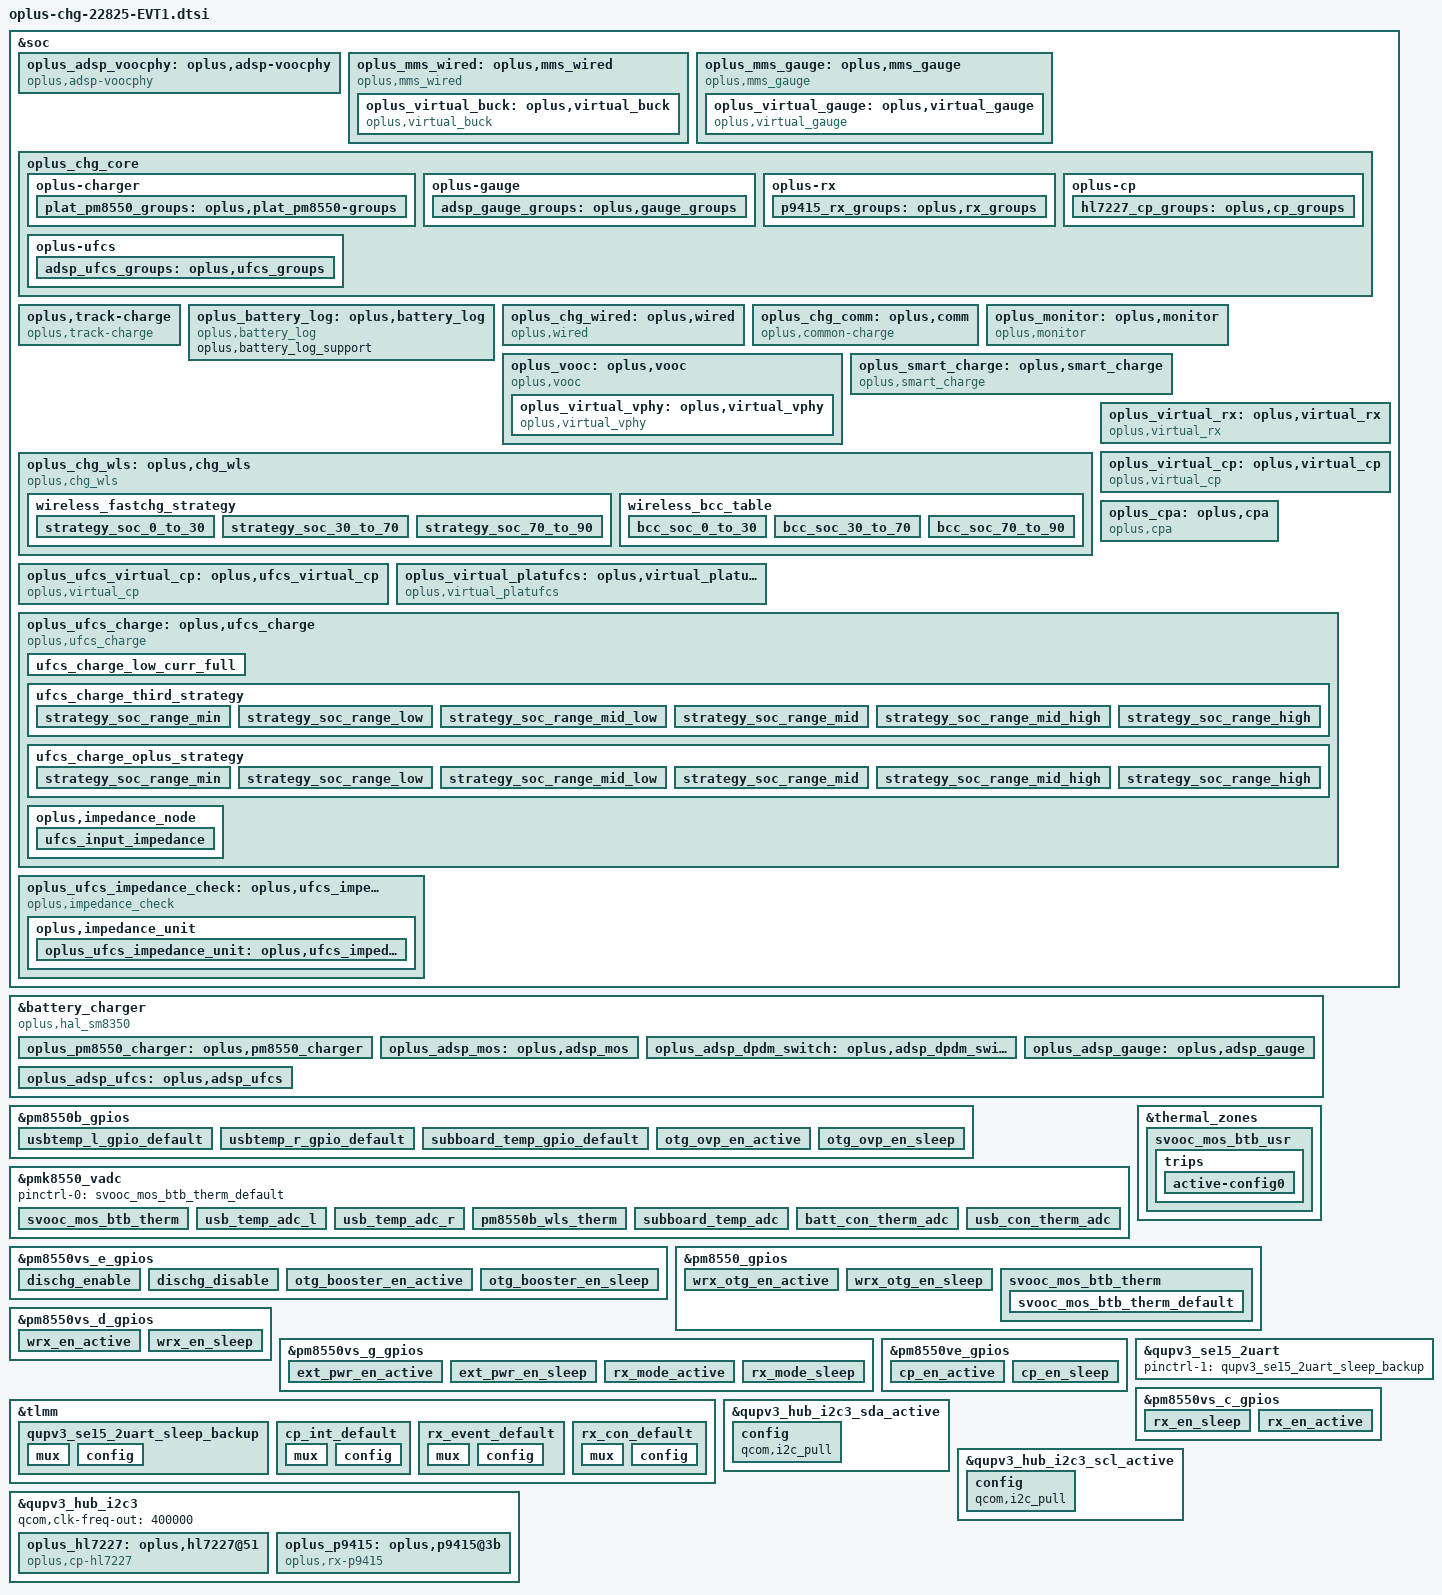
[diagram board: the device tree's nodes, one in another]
//ifdef OPLUS_FEATURE_CHG_BASIC
//BSP.CHG.Basic, 2023/04/19, sjc Add for charging

#include "oplus-chg-8650.h.dtsi"
#include "oplus-chg-22825-fw.dtsi"

/*
 * NOTICE:
 * sector 1: wired charging
 * sector 2: wls charging
 * sector 3: ufcs
 */

//#ifdef OPLUS_FEATURE_CHG_BASIC /* BSP.CHG.Basic, 2023/04/19, sjc Add for wired charging */
//for wired charging config
&soc {
	oplus_adsp_voocphy: oplus,adsp-voocphy {
		compatible = "oplus,adsp-voocphy";
		oplus,ic_type = <OPLUS_CHG_IC_VPHY>;
		oplus,ic_index = <0>;
		oplus,vooc-version = <VOOC_VERSION_5_0>;

		oplus_spec,vooc_low_temp = <0>;
		oplus_spec,vooc_little_cold_temp = <50>;
		oplus_spec,vooc_cool_temp = <120>;
		oplus_spec,vooc_little_cool_temp = <200>;
		oplus_spec,vooc_normal_low_temp = <350>;
		oplus_spec,vooc_normal_high_temp = <440>;
		oplus_spec,vooc_high_temp = <500>;
		oplus_spec,vooc_over_high_temp = <510>;
		oplus_spec,vooc_low_soc = <0>;
		oplus_spec,vooc_high_soc = <90>;

		oplus_spec,vooc_warm_vol_thr = <4000>;
		oplus_spec,vooc_warm_soc_thr = <50>;
	};

	oplus_mms_wired: oplus,mms_wired {
		compatible = "oplus,mms_wired";
		oplus,buck_ic = <&oplus_virtual_buck>;

		oplus,adc_info_name = "855";
		oplus,topic-update-interval = <5000>;

		oplus,support_usbtemp_protect_v2;
		oplus_spec,usbtemp_batt_temp_low = <50>;
		oplus_spec,usbtemp_batt_temp_high = <50>;
		oplus_spec,usbtemp_ntc_temp_low = <57>;
		oplus_spec,usbtemp_ntc_temp_high = <69>;
		oplus_spec,usbtemp_temp_gap_low_with_batt_temp = <7>;
		oplus_spec,usbtemp_temp_gap_high_with_batt_temp = <12>;
		oplus_spec,usbtemp_temp_gap_low_without_batt_temp = <12>;
		oplus_spec,usbtemp_temp_gap_high_without_batt_temp = <24>;
		oplus_spec.usbtemp_rise_fast_temp_low = <3>;
		oplus_spec.usbtemp_rise_fast_temp_high = <3>;
		oplus_spec.usbtemp_rise_fast_temp_count_low = <30>;
		oplus_spec.usbtemp_rise_fast_temp_count_high = <20>;
		oplus_spec,usbtemp_cool_down_ntc_low = <54>;
		oplus_spec,usbtemp_cool_down_ntc_high = <65>;
		oplus_spec,usbtemp_cool_down_gap_low = <12>;
		oplus_spec,usbtemp_cool_down_gap_high = <20>;
		oplus_spec,usbtemp_cool_down_recover_ntc_low = <48>;
		oplus_spec,usbtemp_cool_down_recover_ntc_high = <60>;
		oplus_spec,usbtemp_cool_down_recover_gap_low = <6>;
		oplus_spec,usbtemp_cool_down_recover_gap_high = <15>;

		oplus_virtual_buck: oplus,virtual_buck {
			compatible = "oplus,virtual_buck";
			oplus,buck_ic = <&oplus_pm8550_charger>;
			oplus,buck_ic_index = <0>;
			oplus,buck_ic_connect = <OPLUS_CHG_IC_CONNECT_PARALLEL>;
			oplus,main_charger = <1>;
			oplus,buck_ic_current_ratio = <100>;
			oplus,buck_ic_func_group = <&plat_pm8550_groups>;

			oplus,ic_type = <OPLUS_CHG_IC_VIRTUAL_BUCK>;
			oplus,ic_index = <0>;

			oplus,dischg-gpio = <&pm8550vs_e_gpios 6 0x00>;
			//oplus,ship-gpio = <&tlmm 76 0x00>;

			pinctrl-names = "usbtemp_l_gpio_default", "usbtemp_r_gpio_default",
						"dischg_enable", "dischg_disable";
			pinctrl-0 = <&usbtemp_l_gpio_default>;
			pinctrl-1 = <&usbtemp_r_gpio_default>;
			pinctrl-2 = <&dischg_enable>;
			pinctrl-3 = <&dischg_disable>;

			io-channels = <&pmk8550_vadc PM8550B_ADC5_GEN3_AMUX2_GPIO5_100K_PU>,
					      <&pmk8550_vadc PM8550B_ADC5_GEN3_AMUX_THM6_GPIO10_100K_PU>;
			io-channel-names = "usb_temp_adc_l", "usb_temp_adc_r";

			oplus,uart_tx-gpio = <&tlmm 30 0x00>;
			oplus,uart_rx-gpio = <&tlmm 31 0x00>;
		};
	};
	oplus_mms_gauge: oplus,mms_gauge {
		compatible = "oplus,mms_gauge";
		oplus,gauge_ic = <&oplus_virtual_gauge>;
		oplus,topic-update-interval = <5000>;
		oplus,support_subboard_ntc;

		oplus_virtual_gauge: oplus,virtual_gauge {
			compatible = "oplus,virtual_gauge";
			oplus,gauge_ic = <&oplus_adsp_gauge>;
			oplus,gauge_ic_index = <0>;
			oplus,gauge_ic_func_group = <&adsp_gauge_groups>;
			oplus,batt_capacity_mah = <5400>;
			oplus,ic_type = <OPLUS_CHG_IC_VIRTUAL_GAUGE>;
			oplus,ic_index = <0>;
		};
	};
};

&soc {
	oplus_chg_core {
		oplus,chg_framework_v2;
		oplus,smart_charging_screenoff;

		oplus-charger {
			plat_pm8550_groups: oplus,plat_pm8550-groups {
				functions = <
					OPLUS_IC_FUNC_INIT
					OPLUS_IC_FUNC_EXIT
					OPLUS_IC_FUNC_REG_DUMP
					OPLUS_IC_FUNC_SMT_TEST
					OPLUS_IC_FUNC_BUCK_INPUT_PRESENT
					OPLUS_IC_FUNC_BUCK_INPUT_SUSPEND
					OPLUS_IC_FUNC_BUCK_INPUT_IS_SUSPEND
					OPLUS_IC_FUNC_BUCK_OUTPUT_SUSPEND
					OPLUS_IC_FUNC_BUCK_OUTPUT_IS_SUSPEND
					OPLUS_IC_FUNC_BUCK_GET_CC_ORIENTATION
					OPLUS_IC_FUNC_BUCK_GET_CHARGER_TYPE
					OPLUS_IC_FUNC_BUCK_RERUN_BC12
					OPLUS_IC_FUNC_BUCK_QC_DETECT_ENABLE
					OPLUS_IC_FUNC_BUCK_SHIPMODE_ENABLE
					OPLUS_IC_FUNC_BUCK_SET_QC_CONFIG
					OPLUS_IC_FUNC_BUCK_SET_PD_CONFIG
					OPLUS_IC_FUNC_GET_SHUTDOWN_SOC
					OPLUS_IC_FUNC_BACKUP_SOC
					OPLUS_IC_FUNC_GET_TYPEC_MODE
					OPLUS_IC_FUNC_BUCK_SET_ICL
					OPLUS_IC_FUNC_BUCK_GET_ICL
					OPLUS_IC_FUNC_BUCK_SET_FCC
					OPLUS_IC_FUNC_BUCK_SET_FV
					OPLUS_IC_FUNC_BUCK_SET_ITERM
					OPLUS_IC_FUNC_BUCK_SET_RECHG_VOL
					OPLUS_IC_FUNC_BUCK_GET_INPUT_CURR
					OPLUS_IC_FUNC_BUCK_GET_INPUT_VOL
					OPLUS_IC_FUNC_GET_CHARGER_CYCLE
					OPLUS_IC_FUNC_OTG_BOOST_ENABLE
					OPLUS_IC_FUNC_BUCK_GET_VBUS_COLLAPSE_STATUS
					OPLUS_IC_FUNC_GET_OTG_ENABLE
					OPLUS_IC_FUNC_SET_OTG_SWITCH_STATUS
					OPLUS_IC_FUNC_GET_OTG_SWITCH_STATUS
					OPLUS_IC_FUNC_GET_OTG_ONLINE_STATUS
					OPLUS_IC_FUNC_BUCK_GET_HW_DETECT
					OPLUS_IC_FUNC_VOOCPHY_SET_MATCH_TEMP
					OPLUS_IC_FUNC_IS_OPLUS_SVID
					OPLUS_IC_FUNC_BUCK_SET_VINDPM
					OPLUS_IC_FUNC_WLS_BOOST_ENABLE
					OPLUS_IC_FUNC_SET_WLS_BOOST_VOL
					OPLUS_IC_FUNC_SET_WLS_BOOST_CURR_LIMIT
					OPLUS_IC_FUNC_BUCK_WLS_INPUT_SUSPEND
					OPLUS_IC_FUNC_BUCK_SET_WLS_ICL
					OPLUS_IC_FUNC_BUCK_GET_WLS_ICL
					OPLUS_IC_FUNC_BUCK_GET_WLS_INPUT_CURR
					OPLUS_IC_FUNC_BUCK_GET_WLS_INPUT_VOL
					OPLUS_IC_FUNC_BUCK_WLS_AICL_ENABLE
					OPLUS_IC_FUNC_BUCK_WLS_AICL_RERUN
					OPLUS_IC_FUNC_BUCK_DIS_INSERT_DETECT
					OPLUS_IC_FUNC_GET_TYPEC_ROLE
					OPLUS_IC_FUNC_SET_TYPEC_MODE
					OPLUS_IC_FUNC_BUCK_GET_USB_BTB_TEMP
					OPLUS_IC_FUNC_BUCK_GET_BATT_BTB_TEMP
				>;
				virqs = <
					OPLUS_IC_VIRQ_ERR
					OPLUS_IC_VIRQ_CC_DETECT
					OPLUS_IC_VIRQ_PLUGIN
					OPLUS_IC_VIRQ_CC_CHANGED
					OPLUS_IC_VIRQ_SUSPEND_CHECK
					OPLUS_IC_VIRQ_CHG_TYPE_CHANGE
					OPLUS_IC_VIRQ_OTG_ENABLE
					OPLUS_IC_VIRQ_SVID
				>;
			};
		};

		oplus-gauge {
			adsp_gauge_groups: oplus,gauge_groups {
				functions = <
					OPLUS_IC_FUNC_INIT
					OPLUS_IC_FUNC_EXIT
					OPLUS_IC_FUNC_REG_DUMP
					OPLUS_IC_FUNC_SMT_TEST
					OPLUS_IC_FUNC_GAUGE_GET_BATT_VOL
					OPLUS_IC_FUNC_GAUGE_GET_BATT_MAX
					OPLUS_IC_FUNC_GAUGE_GET_BATT_MIN
					OPLUS_IC_FUNC_GAUGE_GET_BATT_CURR
					OPLUS_IC_FUNC_GAUGE_GET_BATT_TEMP
					OPLUS_IC_FUNC_GAUGE_GET_BATT_SOC
					OPLUS_IC_FUNC_GAUGE_GET_BATT_FCC
					OPLUS_IC_FUNC_GAUGE_GET_BATT_CC
					OPLUS_IC_FUNC_GAUGE_GET_BATT_RM
					OPLUS_IC_FUNC_GAUGE_GET_BATT_SOH
					OPLUS_IC_FUNC_GAUGE_GET_BATT_AUTH
					OPLUS_IC_FUNC_GAUGE_GET_BATT_HMAC
					OPLUS_IC_FUNC_GAUGE_SET_BATT_FULL
					OPLUS_IC_FUNC_GAUGE_UPDATE_DOD0
					OPLUS_IC_FUNC_GAUGE_UPDATE_SOC_SMOOTH
					OPLUS_IC_FUNC_GAUGE_GET_CB_STATUS
					OPLUS_IC_FUNC_GAUGE_GET_BATT_NUM
					OPLUS_IC_FUNC_GAUGE_GET_DEVICE_TYPE
					OPLUS_IC_FUNC_GAUGE_GET_DEVICE_TYPE_FOR_VOOC
					OPLUS_IC_FUNC_GAUGE_GET_BATT_FCC
					OPLUS_IC_FUNC_GAUGE_UPDATE
					OPLUS_IC_FUNC_GAUGE_IS_SUSPEND
					OPLUS_IC_FUNC_GAUGE_GET_SUBBOARD_TEMP
					OPLUS_IC_FUNC_GAUGE_GET_BCC_PARMS
					OPLUS_IC_FUNC_GAUGE_GET_DEVICE_TYPE_FOR_BCC
					OPLUS_IC_FUNC_GAUGE_GET_DOD0
					OPLUS_IC_FUNC_GAUGE_GET_DOD0_PASSED_Q
					OPLUS_IC_FUNC_GAUGE_GET_QMAX
					OPLUS_IC_FUNC_GAUGE_GET_QMAX_PASSED_Q
				>;
				virqs = <
					OPLUS_IC_VIRQ_ERR
					OPLUS_IC_VIRQ_OFFLINE
					OPLUS_IC_VIRQ_RESUME
				>;
			};
		};

		oplus-rx {
			p9415_rx_groups: oplus,rx_groups {
				functions = <
					OPLUS_IC_FUNC_INIT
					OPLUS_IC_FUNC_EXIT
					OPLUS_IC_FUNC_REG_DUMP
					OPLUS_IC_FUNC_SMT_TEST
					OPLUS_IC_FUNC_RX_SET_ENABLE
					OPLUS_IC_FUNC_RX_IS_ENABLE
					OPLUS_IC_FUNC_RX_IS_CONNECTED
					OPLUS_IC_FUNC_RX_GET_VOUT
					OPLUS_IC_FUNC_RX_SET_VOUT
					OPLUS_IC_FUNC_RX_GET_VRECT
					OPLUS_IC_FUNC_RX_GET_IOUT
					OPLUS_IC_FUNC_RX_GET_TRX_VOL
					OPLUS_IC_FUNC_RX_GET_TRX_CURR
					OPLUS_IC_FUNC_RX_GET_CEP_COUNT
					OPLUS_IC_FUNC_RX_GET_CEP_VAL
					OPLUS_IC_FUNC_RX_GET_WORK_FREQ
					OPLUS_IC_FUNC_RX_GET_RX_MODE
					OPLUS_IC_FUNC_RX_SET_RX_MODE
					OPLUS_IC_FUNC_RX_SET_DCDC_ENABLE
					OPLUS_IC_FUNC_RX_SET_TRX_ENABLE
					//OPLUS_IC_FUNC_RX_SET_TRX_START
					OPLUS_IC_FUNC_RX_GET_TRX_STATUS
					OPLUS_IC_FUNC_RX_GET_TRX_ERR
					OPLUS_IC_FUNC_RX_GET_HEADROOM
					OPLUS_IC_FUNC_RX_SET_HEADROOM
					OPLUS_IC_FUNC_RX_SEND_MATCH_Q
					OPLUS_IC_FUNC_RX_SET_FOD_PARM
					OPLUS_IC_FUNC_RX_SEND_MSG
					OPLUS_IC_FUNC_RX_REG_MSG_CALLBACK
					OPLUS_IC_FUNC_RX_GET_RX_VERSION
					OPLUS_IC_FUNC_RX_GET_TRX_VERSION
					OPLUS_IC_FUNC_RX_UPGRADE_FW_BY_BUF
					OPLUS_IC_FUNC_RX_UPGRADE_FW_BY_IMG
					OPLUS_IC_FUNC_RX_CHECK_CONNECT
					OPLUS_IC_FUNC_RX_GET_EVENT_CODE
				>;
				virqs = <
					OPLUS_IC_VIRQ_ERR
					OPLUS_IC_VIRQ_PRESENT
					OPLUS_IC_VIRQ_ONLINE
					OPLUS_IC_VIRQ_OFFLINE
					OPLUS_IC_VIRQ_EVENT_CHANGED
				>;
			};
		};

		oplus-cp {
			hl7227_cp_groups: oplus,cp_groups {
				functions = <
					OPLUS_IC_FUNC_INIT
					OPLUS_IC_FUNC_EXIT
					OPLUS_IC_FUNC_REG_DUMP
					OPLUS_IC_FUNC_SMT_TEST
					OPLUS_IC_FUNC_CP_ENABLE
					OPLUS_IC_FUNC_CP_SET_WORK_START
				>;
				virqs = <
					OPLUS_IC_VIRQ_ERR
					OPLUS_IC_VIRQ_ONLINE
					OPLUS_IC_VIRQ_OFFLINE
				>;
			};
		};

		oplus-ufcs {
			adsp_ufcs_groups: oplus,ufcs_groups {
				functions = <
					OPLUS_IC_FUNC_INIT
					OPLUS_IC_FUNC_EXIT
					OPLUS_IC_FUNC_REG_DUMP
					OPLUS_IC_FUNC_SMT_TEST
					OPLUS_IC_FUNC_UFCS_HANDSHAKE
					OPLUS_IC_FUNC_UFCS_PDO_SET
					OPLUS_IC_FUNC_UFCS_HARD_RESET
					OPLUS_IC_FUNC_UFCS_EXIT
					OPLUS_IC_FUNC_UFCS_CONFIG_WD
					OPLUS_IC_FUNC_UFCS_GET_DEV_INFO
					OPLUS_IC_FUNC_UFCS_GET_ERR_INFO
					OPLUS_IC_FUNC_UFCS_GET_SRC_INFO
					OPLUS_IC_FUNC_UFCS_GET_CABLE_INFO
					OPLUS_IC_FUNC_UFCS_GET_PDO_INFO
					OPLUS_IC_FUNC_UFCS_VERIFY_ADAPTER
					OPLUS_IC_FUNC_UFCS_GET_POWER_CHANGE_INFO
					OPLUS_IC_FUNC_UFCS_GET_EMARK_INFO
					OPLUS_IC_FUNC_UFCS_GET_POWER_INFO_EXT
					OPLUS_IC_FUNC_UFCS_IS_TEST_MODE
				>;
				virqs = <
					OPLUS_IC_VIRQ_ERR
					OPLUS_IC_VIRQ_ONLINE
					OPLUS_IC_VIRQ_OFFLINE
				>;
			};
		};
	};
};

&soc {
	oplus,track-charge {
		compatible = "oplus,track-charge";
		track,fast_chg_break_t_thd = <1400>;
		track,general_chg_break_t_thd = <300>;
		track,voocphy_type = <1>;
		track,wired_max_power = <100000>;
		track,wired_fast_chg_scheme = <0>;

		track,wls_max_power = <50000>;
		track,wls_bpp_chg_scheme = <0>;
		track,wls_epp_chg_scheme = <0>;
		track,wls_fast_chg_scheme = <0>;
	};
};

&battery_charger {
	//for oplus chg framework:
	oplus,chg_ops = "plat-pmic";
	qcom,pmic_ftm_vph = "/sys/bus/spmi/drivers/pmic-spmi/0-00/c42d000.qcom,spmi:qcom,pmk8550@0:vadc@9000/iio:device0/in_voltage_pm8550b_vph_pwr_input";
	qcom,pmic_ftm_vbat = "/sys/bus/spmi/drivers/pmic-spmi/0-00/c42d000.qcom,spmi:qcom,pmk8550@0:vadc@9000/iio:device0/in_voltage_pm8550b_vbat_sns_qbg_input";


	qcom,otg-booster-en-gpio = <&pm8550vs_e_gpios 4 0x00>;
	qcom,otg-ovp-en-gpio = <&pm8550b_gpios 7 0x00>;
	oplus,wrx_otg_en-gpio = <&pm8550_gpios 1 0x00>;//wls nor OVP check
	pinctrl-names = "otg_booster_en_active", "otg_booster_en_sleep",
			"otg_ovp_en_active", "otg_ovp_en_sleep",
			"subboard_temp_gpio_default",
			"wrx_otg_en_active","wrx_otg_en_sleep";
	pinctrl-0 = <&otg_booster_en_active>;
	pinctrl-1 = <&otg_booster_en_sleep>;
	pinctrl-2 = <&otg_ovp_en_active>;
	pinctrl-3 = <&otg_ovp_en_sleep>;
	pinctrl-4 = <&subboard_temp_gpio_default>;
	pinctrl-5 = <&wrx_otg_en_active>;
	pinctrl-6 = <&wrx_otg_en_sleep>;

};

&battery_charger {
	compatible = "oplus,hal_sm8350";
	oplus,vphy_ic = <&oplus_adsp_voocphy>;
	oplus,voocphy_support;
	oplus,vooc_project = <8>;
	oplus,batt_num = <2>;
	oplus,otg_scheme = <0>;//0:cid 1:ccdetect_gpio 2:switch
	oplus_pm8550_charger: oplus,pm8550_charger {
		oplus,ic_type = <OPLUS_CHG_IC_BUCK>;
		oplus,ic_index = <0>;
	};
	oplus_adsp_mos: oplus,adsp_mos {
		oplus,ic_type = <OPLUS_CHG_IC_CP>;
		oplus,ic_index = <0>;
	};

	oplus_adsp_dpdm_switch: oplus,adsp_dpdm_switch {
		oplus,ic_type = <OPLUS_CHG_IC_MISC>;
		oplus,ic_index = <0>;
	};
	oplus_adsp_gauge: oplus,adsp_gauge {
		oplus,ic_type = <OPLUS_CHG_IC_GAUGE>;
		oplus,ic_index = <0>;
	};
	oplus_adsp_ufcs: oplus,adsp_ufcs {
		oplus,ic_type = <OPLUS_CHG_IC_UFCS>;
		oplus,ic_index = <0>;
	};
};

&soc {
	oplus_battery_log: oplus,battery_log {
		compatible = "oplus,battery_log";

		oplus,battery_log_support;
	};

	oplus_chg_wired: oplus,wired {
		compatible = "oplus,wired";

		oplus,vooc-support;

		oplus_spec,vbatt_pdqc_to_5v_thr = <5100>;
		oplus_spec,vbatt_pdqc_to_9v_thr = <5000>;
		oplus_spec,pd-iclmax-ma = <2000>;
		oplus_spec,qc-iclmax-ma = <2000>;
		oplus_spec,non-standard-ibatmax-ma = <500>;
		oplus_spec,input-power-mw = <
			2500		/* OPLUS_WIRED_CHG_MODE_UNKNOWN */
			2500		/* OPLUS_WIRED_CHG_MODE_SDP */
			7500		/* OPLUS_WIRED_CHG_MODE_CDP */
			10000		/* OPLUS_WIRED_CHG_MODE_DCP */
			18000		/* OPLUS_WIRED_CHG_MODE_VOOC */
			18000		/* OPLUS_WIRED_CHG_MODE_QC */
			18000		/* OPLUS_WIRED_CHG_MODE_PD */
		>;
		oplus_spec,led_on-fccmax-ma = <0 555 2000 2500 2500 2500 500 0>;
		oplus_spec,fccmax-ma-lv = <
			0 600  1100 1100 1100 1100 1100 0	/* OPLUS_WIRED_CHG_MODE_UNKNOWN */
			0 300  300  300  300  300  300  0	/* OPLUS_WIRED_CHG_MODE_SDP */
			0 600  800  800  800  800  800  0	/* OPLUS_WIRED_CHG_MODE_CDP */
			0 600  1100 1100 1100 1100 1100 0	/* OPLUS_WIRED_CHG_MODE_DCP */
			0 600  1800 1800 1800 1800 1100 0	/* OPLUS_WIRED_CHG_MODE_VOOC */
			0 600  2000 2000 2000 2000 1100 0	/* OPLUS_WIRED_CHG_MODE_QC */
			0 600  2000 2000 2000 2000 1100 0	/* OPLUS_WIRED_CHG_MODE_PD */
		>;
		oplus_spec,fccmax-ma-hv = <
			0 600  1100 1100 1100 1100 1100 0	/* OPLUS_WIRED_CHG_MODE_UNKNOWN */
			0 300  300  300  300  300  300  0	/* OPLUS_WIRED_CHG_MODE_SDP */
			0 600  800  800  800  800  800  0	/* OPLUS_WIRED_CHG_MODE_CDP */
			0 600  1100 1100 1100 1100 1100 0	/* OPLUS_WIRED_CHG_MODE_DCP */
			0 600  1800 1800 1800 1800 1100 0	/* OPLUS_WIRED_CHG_MODE_VOOC */
			0 600  2000 2000 2000 2000 1100 0	/* OPLUS_WIRED_CHG_MODE_QC */
			0 600  2000 2000 2000 2000 1100 0	/* OPLUS_WIRED_CHG_MODE_PD */
		>;

		oplus_spec,cool_down_pdqc_vol_mv = <9000 9000 9000>;
		oplus_spec,cool_down_pdqc_curr_ma = <1200 1500 2000>;
		oplus_spec,cool_down_vooc_curr_ma = <1200 1500 2000 2500 3000 3600>;
		oplus_spec,cool_down_normal_curr_ma = <1200 1500 2000>;

		oplus_spec,vbus_ov_thr_mv = <11000 11000>;
		oplus_spec,vbus_uv_thr_mv = <4300 4300>;

		/* first data is strategy used temp type */
		oplus,vooc_strategy_name = "cgcl";
		oplus,vooc_strategy_data = <OPLUS_STRATEGY_USE_BATT_TEMP
					    0   350 3600 1 0
					    330 370 3200 2 0
					    350 440 2200 2 1>;
	};

	oplus_chg_comm: oplus,comm {
		compatible = "oplus,common-charge";
		oplus_spec,batt-them-thr = <(-100) 0 50 120 160 450 530>;
		oplus_spec,iterm-ma = <142>;
		oplus_spec,fv-mv = <4470 4470 4470 4470 4470 4470 4130 4130>;
		oplus_spec,sw-fv-mv = <4420 4420 4420 4420 4420 4420 4080 4080>;
		oplus_spec,hw-fv-inc-mv = <0 18 18 18 18 18 18 0>;
		oplus_spec,sw-over-fv-mv = <4480 4480 4480 4480 4480 4480 4140 4140>;
		oplus_spec,sw-over-fv-dec-mv = <10>;
		oplus_spec,non-standard-sw-fv-mv = <3930>;
		oplus_spec,non-standard-fv-mv = <3980>;
		oplus_spec,non-standard-hw-fv-inc-mv = <18>;
		oplus_spec,non-standard-sw-over-fv-mv = <3990>;
		oplus_spec,non-standard-vbatdet-mv = <3600>;
		oplus_spec,wired-vbatdet-mv = <0 4170 4270 4370 4370 4370 4030 0>;
		oplus_spec,wls-vbatdet-mv = <0 4170 4270 4370 4370 4370 4030 0>;
		oplus_spec,fcc-gear-thr-mv = <4180>;
		oplus_spec,vbatt-ov-thr-mv = <4600>;
		oplus_spec,full_pre_ffc_judge;
		oplus_spec,full-pre-ffc-mv = <4465>;
		oplus_spec,ffc-temp-thr = <120 350 400>;
		oplus_spec,wired-ffc-step-max = <2>;
		oplus_spec,wired-ffc-fv-mv = <4560 4560>;

		oplus_spec,wired-ffc-fv-cutoff-mv = <4483 4483 4470 4470>;

		oplus_spec,removed_bat_decidegc = <390>;

		oplus_spec,wired-ffc-fcc-ma = <550 550
					       350 350>;
		oplus_spec,wired-ffc-fcc-cutoff-ma = <400 400
						      200 200>;

		/* 2s battery */
		oplus_spec,wired-aging-ffc-version = <AGING_FFC_V1>;
		oplus_spec,wired-aging-ffc-offset-mv = <15 30
							10 20>;
		oplus_spec,wired-aging-ffc-cycle-thr = <500 1000>;

		oplus_spec,wls-ffc-step-max = <2>;
		oplus_spec,wls-ffc-fv-mv = <4560 4560>;
		oplus_spec,wls-ffc-fv-cutoff-mv = <4483 4470>;
		oplus_spec,wls-ffc-icl-ma = <500 500
					     400  400>;
		oplus_spec,wls-ffc-fcc-ma = <550 550
					     350 350>;
		oplus_spec,wls-ffc-fcc-cutoff-ma = <400 400
						    200 200>;
		oplus_spec,vbat_uv_thr_mv = <3300>;
		oplus_spec,vbat_charging_uv_thr_mv = <3200>;

		/*If use subboard NTC as battery temp, config it as 20, otherwise 0 */
		oplus_spec,tbatt_power_off_cali_temp = <20>;
		oplus,vooc_show_ui_soc_decimal;
		oplus,ui_soc_decimal_speedmin = <20>;

		oplus,gauge_stuck_jump_support;
		oplus,gauge_stuck_threshold = <15>;
		oplus,gauge_stuck_time = <50>;

		oplus,smooth_switch;
		oplus,reserve_chg_soc = <3>;
		oplus,reserve_dis_soc = <3>;
	};

	oplus_monitor: oplus,monitor {
		compatible = "oplus,monitor";
		oplus,topic-update-interval = <60000>;

		track,fast_chg_break_t_thd = <1400>;
		track,general_chg_break_t_thd = <300>;
		track,voocphy_type = <2>;
		track,wired_max_power = <100000>;
		track,wired_fast_chg_scheme = <0>;
	};

	oplus_vooc: oplus,vooc {
		compatible = "oplus,vooc";
		oplus,vooc_ic = <&oplus_virtual_vphy>;

		oplus_spec,vooc_soc_range = <50 75 85>;
		oplus_spec,vooc_temp_range = <50 120 180 350 450>;

		oplus,vooc_data_width = <7>;
		oplus,vooc_curr_max = <CURR_LIMIT_7BIT_9_5A>;
		oplus,support_vooc_by_normal_charger_path;
		oplus,vooc_project = <8>;
		oplus,vooc_power_max_w = <100>;
		oplus,voocphy_support = <1>;
		oplus,support_fake_vooc_check;

		oplus,smart_chg_bcc_support;

		oplus,abnormal_adapter_current = <CURR_LIMIT_7BIT_9_5A CURR_LIMIT_7BIT_9_5A
						CURR_LIMIT_7BIT_5_0A CURR_LIMIT_7BIT_5_0A
						CURR_LIMIT_7BIT_4_0A CURR_LIMIT_7BIT_4_0A
						CURR_LIMIT_7BIT_3_0A CURR_LIMIT_7BIT_3_0A
						CURR_LIMIT_7BIT_2_0A CURR_LIMIT_7BIT_2_0A>;

		oplus,general_strategy_name = "cgcl";
		oplus,general_strategy_data = < OPLUS_STRATEGY_USE_SHELL_TEMP
						0   380 CURR_LIMIT_7BIT_9_5A 1 0
						370 400 CURR_LIMIT_7BIT_7_0A 2 0
						390 420 CURR_LIMIT_7BIT_5_0A 3 1
						410 430 CURR_LIMIT_7BIT_4_0A 4 2
						420 440 CURR_LIMIT_7BIT_3_0A 4 3 >;

		oplus_virtual_vphy: oplus,virtual_vphy {
			compatible = "oplus,virtual_vphy";
			oplus,vphy_ic = <&oplus_adsp_voocphy>;

			oplus,ic_type = <OPLUS_CHG_IC_VIRTUAL_VPHY>;
			oplus,ic_index = <0>;
		};
	};
	oplus_smart_charge: oplus,smart_charge {
		compatible = "oplus,smart_charge";
		oplus,quick_mode_gain_support;
		oplus,smart_chg_soh_support;
	};
};

&pm8550b_gpios {
	usbtemp_l_gpio_default: usbtemp_l_gpio_default {
		pins = "gpio5"; //GPIO 5
		function = "normal"; //normal
		bias-high-impedance; //DISABLE GPIO5 for ADC
		bias-disable;
	};
	usbtemp_r_gpio_default: usbtemp_r_gpio_default {
		pins = "gpio10"; //GPIO 10
		function = "normal"; //normal
		bias-high-impedance; //DISABLE GPIO10 for ADC
		bias-disable;
	};
	subboard_temp_gpio_default: subboard_temp_gpio_default {
		pins = "gpio6"; //GPIO 6
		function = "normal"; //normal
		bias-high-impedance; //DISABLE GPIO6 for ADC
		bias-disable;
	};
};

&pmk8550_vadc {
	pinctrl-0 = <&svooc_mos_btb_therm_default>;
	pinctrl-names = "default";

	svooc_mos_btb_therm {
		reg = <PM8550_ADC5_GEN3_AMUX4_GPIO12_100K_PU>;
		label = "svooc_mos_btb_therm";
		qcom,ratiometric;
		qcom,hw-settle-time = <200>;
		qcom,pre-scaling = <1 1>;
		qcom,adc-tm-type = <1>;
	};
	usb_temp_adc_l {
		reg = <PM8550B_ADC5_GEN3_AMUX2_GPIO5_100K_PU>;
		label = "usb_temp_adc_l";
		qcom,pre-scaling = <1 1>;
		qcom,ratiometric;
		qcom,hw-settle-time = <200>;
		qcom,scale-fn-type = <OPLUS_ADC_SCALE_HW_CALIB_DEFAULT>;
	};
	usb_temp_adc_r {
		reg = <PM8550B_ADC5_GEN3_AMUX_THM6_GPIO10_100K_PU>;
		label = "usb_temp_adc_r";
		qcom,pre-scaling = <1 1>;
		qcom,ratiometric;
		qcom,hw-settle-time = <200>;
		qcom,scale-fn-type = <OPLUS_ADC_SCALE_HW_CALIB_DEFAULT>;
	};
	pm8550b_wls_therm { //for PM8550B_ADC5_GEN3_AMUX_THM6_GPIO10_100K_PU to config to uV
		qcom,adc-tm-type = <0>;
		qcom,scale-fn-type = <OPLUS_ADC_SCALE_HW_CALIB_DEFAULT>;
	};
	subboard_temp_adc {
		reg = <PM8550B_ADC5_GEN3_AMUX3_GPIO6_100K_PU>;
		label = "subboard_temp_adc";
		qcom,pre-scaling = <1 1>;
		qcom,ratiometric;
		qcom,hw-settle-time = <200>;
	};
	batt_con_therm_adc {
		reg = <PM8550B_ADC5_GEN3_AMUX_THM1_BATT_THERM_100K_PU>;
		label = "batt_con_therm_adc";
		qcom,ratiometric;
		qcom,hw-settle-time = <200>;
		qcom,pre-scaling = <1 1>;
		qcom,adc-tm-type = <1>;
	};
	usb_con_therm_adc {
		reg = <PM8550B_ADC5_GEN3_AMUX_THM4_USB_THERM_100K_PU>;
		label = "usb_con_therm_adc";
		qcom,ratiometric;
		qcom,hw-settle-time = <200>;
		qcom,pre-scaling = <1 1>;
		qcom,adc-tm-type = <1>;
	};
};

&thermal_zones {
	svooc_mos_btb_usr {
		polling-delay-passive = <0>;
		polling-delay = <0>;
		thermal-governor = "user_space";
		thermal-sensors = <&pmk8550_vadc PM8550_ADC5_GEN3_AMUX4_GPIO12_100K_PU>;
		wake-capable-sensor;
		trips {
			active-config0 {
				temperature = <125000>;
				hysteresis = <1000>;
				type = "passive";
			};
		};
	};
};

&battery_charger {
	io-channels	= <&pmk8550_vadc PM8550B_ADC5_GEN3_AMUX2_GPIO5_100K_PU>,
					<&pmk8550_vadc PM8550B_ADC5_GEN3_AMUX_THM6_GPIO10_100K_PU>,
					<&pmk8550_vadc PM8550B_ADC5_GEN3_AMUX3_GPIO6_100K_PU>,
					<&pmk8550_vadc PM8550B_ADC5_GEN3_AMUX_THM1_BATT_THERM_100K_PU>,
					<&pmk8550_vadc PM8550B_ADC5_GEN3_AMUX_THM4_USB_THERM_100K_PU>;
	io-channel-names = "usb_temp_adc_l", "usb_temp_adc_r", "subboard_temp_adc",
				       "batt_con_therm_adc", "usb_con_therm_adc";
};

&pm8550vs_e_gpios {
	dischg_enable: dischg_enable {
		pins = "gpio6";
		function = "normal";
		bias-disable;
		power-source = <0>;
		output-high;
		qcom,drive-strength = <3>;
	};
	dischg_disable: dischg_disable {
		pins = "gpio6";
		function = "normal";
		bias-disable;
		power-source = <0>;
		output-low;
		qcom,drive-strength = <3>;
	};
};

&pm8550vs_e_gpios {
	otg_booster_en_active: otg_booster_en_active {
		pins = "gpio4";
		function = "normal";
		bias-disable;
		power-source = <0>;
		output-high;
		qcom,drive-strength = <3>;
	};
	otg_booster_en_sleep: otg_booster_en_sleep {
		pins = "gpio4";
		function = "normal";
		bias-disable;
		power-source = <0>;
		output-low;
		qcom,drive-strength = <3>;
	};
};

&pm8550b_gpios {
	otg_ovp_en_active: otg_ovp_en_active {
		pins = "gpio7";
		function = "normal";
		bias-disable;
		power-source = <0>;
		output-high;
		qcom,drive-strength = <3>;
	};
	otg_ovp_en_sleep: otg_ovp_en_sleep {
		pins = "gpio7";
		function = "normal";
		bias-disable;
		power-source = <0>;
		output-low;
		qcom,drive-strength = <3>;
	};
};
//#endif OPLUS_FEATURE_CHG_BASIC /*for wired charging config*/


//#ifdef OPLUS_FEATURE_CHG_BASIC /* BSP.CHG.Basic, 2023/04/19, sjc Add for wls charging */
//for wls charging config
&pm8550_gpios {
	wrx_otg_en_active: wrx_otg_en_active {
		pins = "gpio1";
		function = "normal";
		bias-disable;
		power-source = <0>;
		output-high;
		qcom,drive-strength = <3>;
	};
	wrx_otg_en_sleep: wrx_otg_en_sleep {
		pins = "gpio1";
		function = "normal";
		bias-disable;
		power-source = <0>;
		output-low;
		qcom,drive-strength = <3>;
	};
	svooc_mos_btb_therm {
		svooc_mos_btb_therm_default: svooc_mos_btb_therm_default {
			pins = "gpio12";
			function = "normal"; //normal
			bias-high-impedance;
			bias-disable;
		};
	};
};

&battery_charger {
	oplus,wls_boost_soft_start;
	//oplus,wls_boost_vol_start_mv = <6000>;
	oplus,wls_boost_vol_max_mv = <7500>;

	//oplus,tx_boost_en-gpio = <&pm8550vs_e_gpios 7 0x00>;//it is otg-booster-en-gpio
	//oplus,tx_ovp_en-gpio = <&pm8550b_gpios 4 0x00>;//
	//oplus,wrx_ovp_off-gpio = <&tlmm 72 0x00>;//pm8350c
};

&pm8550vs_d_gpios {
	wrx_en_active: wrx_en_active {
		pins = "gpio3";
		function = "normal";
		bias-disable;
		power-source = <1>;
		output-high;
		qcom,drive-strength = <3>;
	};
	wrx_en_sleep: wrx_en_sleep {
		pins = "gpio3";
		function = "normal";
		bias-disable;
		power-source = <1>;
		output-low;
		qcom,drive-strength = <3>;
	};
};

&pm8550vs_g_gpios {
	ext_pwr_en_active: ext_pwr_en_active {
		pins = "gpio3";
		function = "normal";
		bias-disable;
		power-source = <0>;
		output-high;
		qcom,drive-strength = <3>;
	};
	ext_pwr_en_sleep: ext_pwr_en_sleep {
		pins = "gpio3";
		function = "normal";
		bias-disable;
		power-source = <0>;
		output-low;
		qcom,drive-strength = <3>;
	};
};

&soc {
	oplus_chg_wls: oplus,chg_wls {
		status = "ok";
		compatible = "oplus,chg_wls";

		oplus,rx_ic = <&oplus_virtual_rx>;
		oplus,nor_ic = <&oplus_virtual_buck>;
		oplus,fast_ic = <&oplus_virtual_cp>;

		oplus,support_fastchg;
		oplus,support_epp_plus;
		// oplus,support_wls_and_tx_boost;
		oplus,support_wls_chg_bcc;

		oplus,wrx_en-gpio = <&pm8550vs_d_gpios 3 0x00>;//wired nor OVP check
		oplus,ext_pwr_en-gpio = <&pm8550vs_g_gpios 3 0x00>;//ext pwr to reduce rx temp
		pinctrl-names = "wrx_en_active", "wrx_en_sleep",
				"ext_pwr_en_active", "ext_pwr_en_sleep";
		pinctrl-0 = <&wrx_en_active>;
		pinctrl-1 = <&wrx_en_sleep>;
		pinctrl-2 = <&ext_pwr_en_active>;
		pinctrl-3 = <&ext_pwr_en_sleep>;

		oplus,max-voltage-mv = <4550>;
		oplus,fastchg_curr_max_ma = <2500>;
		oplus,wls-fast-chg-call-on-curr-ma = <600>;
		oplus,wls-fast-chg-camera-on-curr-ma = <600>;
		oplus,wls_power_mw = <50000>;
		oplus,wls_phone_id = <0x0F>;
		oplus,wls-bcc-fcc-to-icl-factor = <2>;
		/*
		 * | temp_min | temp_max | target_curr_ma(mA) |
		 *
		 * temp_min: Switch to the previous level when the temperature is lower
		 *           than this value. If it is 0, do not switch.
		 * temp_max: Switch to the next level when the temperature is greater
		 *           than this value
		 */
		oplus,epp_plus-skin-step = <0 360 900
					    350 380 900
					    360 390 900
					    370 410 900>;
		oplus,epp-skin-step = <0 390 800
				       360 400 800>;
		oplus,bpp-skin-step = <0 390 750
				       370 400 750>;
		oplus,epp_plus-led-on-skin-step = <0 390 900
						   380 500 900>;
		oplus,epp-led-on-skin-step = <0 390 800
					      380 500 800>;

		/*
		 * | cool_temp | heat_temp | curr_data | heat_next_index | cool_next_index |
		 */
		oplus,wls-fast-chg-led-off-strategy-data = <0 410 2500 1 0
							    390 450 1200 1 0>;
		oplus,wls-fast-chg-led-on-strategy-data = <0 340 2500 1 0
							   330 360 1000 2 0
							   350 380 800 3 1
							   370 400 600 3 2>;

		oplus,iclmax-ma = <300 750 750 750 750 750 750 750 300    /*wls-bpp(mA)*/
				   300 400 800 800 800 800 800 400 300    /*wls-epp(mA)*/
				   300 400 900 900 900 900 900 400 300    /*wls-epp-plus(mA)*/
				   300 750 950 950 950 950 950 750 300    /*wls-airvooc(mA)*/
				   300 400 1000 1250 2500 2500 2500 400 300>;  /*wls-airsvooc(mA)*/
		oplus,iclmax-batt-high-ma = <300 750 750 750 750 750 750 750 300    /*wls-bpp(mA)*/
					     300 400 800 800 800 800 800 400 300    /*wls-epp(mA)*/
					     300 400 900 900 900 900 900 400 300    /*wls-epp-plus(mA)*/
					     300 750 950 950 950 950 950 750 300    /*wls-airvooc(mA)*/
					     300 400 1000 1250 2500 2500 2500 400 300>;  /*wls-airsvooc(mA)*/

		/*
		 * | temp_min | temp_max | target_curr_ma | vol_max_mv | need wait |
		 * temp_min/temp_max: not use here
		 * target_curr_ma: wls icl when vbat < vol_max_mv
		 * vol_max_mv: the last value is always 5000mV(must be greater than the max-vbat)
		 * need wait: not use here
		 */
		non-ffc-bpp =		<0 0 750  5000 0>;
		non-ffc-epp =		<0 0 800  4385 0
					0 0 400  5000 0>;
		non-ffc-epp-plus =	<0 0 900 4380 0
					0 0 800  4385 0
					0 0 400  5000 0>;
		non-ffc-airvooc =	<0 0 950  4375 0
					0 0 400  5000 0>;
		non-ffc-airsvooc =	<0 0 950  4375 0
					0 0 400  5000 0>;
		/*
		 * | temp_min | temp_max | target_curr_ma | vol_max_mv | need wait |
		 * temp_min: Switch to the previous level when the temperature is lower
		 *           than this value. If it is 0, do not switch.
		 * temp_max: Switch to the next level when the temperature is higher
		 *           than this value
		 * target_curr_ma: wls icl when vbat > vol_max_mv
		 * vol_max_mv: Maximum battery voltage.
		 * need wait: not use here
		 */
		cv-bpp =	<0   450 400 4435 0
				450 530 400 4100 0>;
		cv-epp =	<0   450 300 4435 0
				450 530 300 4100 0>;
		cv-epp-plus =	<0   450 300 4435 0
				450 530 300 4100 0>;
		cv-airvooc =	<0   450 300 4435 0
				450 530 300 4100 0>;
		cv-airsvooc =	<0   450 300 4435 0
				450 530 300 4100 0>;

		oplus,cool-down-12v-thr = <2>;//switch to 12V level
		cool-down-bpp = <0 750 750 750 750 750 750>;
		cool-down-epp = <0 400 400 800 800 800 800>;
		cool-down-epp-plus = <0 400 400 800 800 800 900>;
		cool-down-airvooc = <0 400 400 950 950 950 950>;
		cool-down-airsvooc = <0 400 950 750 750 1000 1250 1500 1500 2000 2000 2500 2500>;

		/*
		 * | bcc_stop_curr |
		 * The three parameters of each array
		 * correspond to three temperature intervals: 0-5; 5-12; 12-44
		 */
		bcc_stop_curr_0_to_30 = <1000 1000 1300 1300 1300>;
		bcc_stop_curr_30_to_70 = <1000 1000 1300 1300 1300>;
		bcc_stop_curr_70_to_90 = <1000 1000 1300 1300 1300>;

		/*
		 * | curr_ma | fallback_step | switch_to_bpp
		 * curr_ma: wls icl in this step
		 * fallback_step: 0: don't fallback when CEP is OK
		 *                1/2...: fallback to 1st/2nd step when CEP is OK
		 * switch_to_bpp: reach the final step, switch to bpp when CEP is not OK
		 */
		skewing-epp =		<800 0 0
					600 0 0
					400 1 0>;
		skewing-epp-plus =	<900 0 0
					800 0 0
					600 2 0
					400 3 0>;//fallback to 800(2nd step) when CEP is OK at this step
		skewing-airvooc =	<950 0 0
					400 0 0>;

		/* fod parameter*/
		/*
		 * oplus,fastchg-match-q: | wls_base(dock) id | q value |
		 */

		oplus,fastchg-fod-enable;
		oplus,fastchg-match-q = /bits/ 8 <0x00 0x33
						0x01 0x39
						0x02 0x44
						0x03 0x44
						0x1f 0x44>;
		oplus,fastchg-fod-parm = /bits/ 8 <0xff 0x7f 0xff 0x7f 0xa1 0x10
						   0x9e 0x7f 0xae 0x00 0xa8 0x7f
						   0xa7 0x40>;

		oplus,disable-fod-parm = /bits/ 8 <0xff 0x7f 0xff 0x7f 0xff 0x7f
						   0xff 0x7f 0xff 0x7f 0xff 0x7f
						   0xff 0x7f>;

		oplus,bpp-vol-mv = <5000>;
		oplus,epp-vol-mv = <12000>;
		oplus,epp_plus-vol-mv = <12000>;
		oplus,vooc-vol-mv = <12000>;
		oplus,svooc-vol-mv = <20000>;

		oplus,fastchg-max-soc = <94>;
		oplus,fastchg-max-temp = <440>;
		oplus,strategy_soc = <30 85 95>;
		/*
		 * | temp_min | temp_max | icl_curr | fcc_curr | need_wait |
		 */
		oplus,wls_epp_plus_strategy = <0   375 900 1100 1
					       350 410 800  1000 1
					       370 430 600  800  1
					       400 530 400  500  1>;
		oplus,wls_epp_strategy = <0   375 800 1000 1
					  350 410 800 1000 1
					  370 430 600 800  1
					  400 530 400 500  1>;

		/*
		 * | temp_min | temp_max | target_curr_ma | vol_max_mv |need wait | soc_max |
		 *
		 * temp_min: Switch to the previous level when the temperature is lower
		 *           than this value. If it is 0, do not switch.
		 * temp_max: Switch to the next level when the temperature is greater
		 *           than this value
		 * target_curr_ma: Target current in this temperature range.
		 * vol_max_mv: Maximum battery voltage.
		 * need wait: 1:Need wait for a while after switching to the next level.
		 *            0:No need to wait after switching to the next level.
		 */
		wireless_fastchg_strategy {
			strategy_soc_0_to_30 {
				strategy_temp_0_to_50 =		<0 370 1500 4154 1
								 0 385 1250 4354 1
								 0 420 1000 4354 1
								 0 430 750  4534 1
								 0 440 500  4544 0>;
				strategy_temp_50_to_120 =	<50 360 1750 4154 1
								 50 370 1500 4354 1
								 50 385 1250 4354 1
								 50 420 1000 4354 1
								 50 430 750  4534 1
								 50 440 500  4544 0>;
				strategy_temp_120_to_160 = 	<120 300 2500 4484 1
								 290 335 2000 4484 1
								 320 360 1750 4534 1
								 330 370 1500 4534 1
								 340 385 1250 4534 1
								 360 420 1000 4534 1
								 400 430 750  4534 1
								 420 440 500  4544 0>;
				strategy_temp_160_to_400 =      <120 300 2500 4484 1
								 290 335 2000 4484 1
								 320 360 1750 4534 1
								 330 370 1500 4534 1
								 340 385 1250 4534 1
								 360 420 1000 4534 1
								 400 430 800  4544 0>;
				strategy_temp_400_to_440 =      <120 300 2500 4484 1
								 290 335 2000 4484 1
								 320 360 1750 4534 1
								 330 370 1500 4534 1
								 340 385 1250 4534 1
								 360 420 1000 4534 1
								 400 430 800  4544 0>;
			};

			strategy_soc_30_to_70 {
				strategy_temp_0_to_50 =		<0 430 750  4534 1
								 0 440 500  4544 0>;
				strategy_temp_50_to_120 =	<50 430 750 4534 1
								 50 440 500  4544 0>;
				strategy_temp_120_to_160 =	<120 360 1750 4534 1
								 330 370 1500 4534 1
								 340 385 1250 4534 1
								 360 420 1000 4534 1
								 400 430 750  4534 1
								 420 440 500  4544 0>;
				strategy_temp_160_to_400 =	<120 360 1750 4534 1
								 330 370 1500 4534 1
								 340 385 1250 4534 1
								 360 420 1000 4534 1
								 400 430 800  4544 0>;
				strategy_temp_400_to_440 =	<120 360 1750 4534 1
								 330 370 1500 4534 1
								 340 385 1250 4534 1
								 360 420 1000 4534 1
								 400 430 800  4544 0>;
			};

			strategy_soc_70_to_90 {
				strategy_temp_0_to_50 =		<0  440 500 4544 0>;
				strategy_temp_50_to_120 =	<50 440 500 4544 0>;
				strategy_temp_120_to_160 =	<120 420 1000 4534 1
								 400 430 750  4534 1
								 420 440 500  4544 0>;
				strategy_temp_160_to_400 =	<120 420 1000 4534 1
								 400 430 800  4544 0>;
				strategy_temp_400_to_440 =	<120 420 1000 4534 1
								 400 430 800  4544 0>;
			};
		};

		/*
		 * | max_batt_volt | max_current | min_current | end
		 *
		 * max_batt_volt: Maximum battery voltage.
		 * max_current: The maximum current in this interval.
		 * min_current: The result obtained by subtracting 1A from the
		 *				minimum current in this interval. Minimum not less than 1A.
		 * exit: Whether the curve ends or not.
		 */
		wireless_bcc_table {
			bcc_soc_0_to_30 {
				bcc_temp_0_to_50 =	<4184 2000 1000 0
							 4454 1500 1000 0
							 4460 1000 1000 1>;
				bcc_temp_50_to_120 =	<4184 2500 1000 0
							 4454 2000 1000 0
							 4460 1000 1000 1>;
				bcc_temp_120_to_160 =	<4184 5000 3500 0
							 4484 4000 3000 0
							 4514 3000 1000 0
							 4520 1300 1000 1>;
				bcc_temp_160_to_400 =	<4184 5000 3500 0
							 4454 4000 3000 0
							 4514 3000 1000 0
							 4520 1300 1000 1>;
				bcc_temp_400_to_440 =	<4184 5000 3500 0
							 4454 4000 3000 0
							 4514 3000 1000 0
							 4520 1300 1000 1>;
			};

			bcc_soc_30_to_70 {
				bcc_temp_0_to_50 =	<4454 1500 1000 0
							 4460 1000 1000 1>;
				bcc_temp_50_to_120 =	<4454 2000 1000 0
							 4460 1000 1000 1>;
				bcc_temp_120_to_160 =	<4484 4000 3000 0
							 4514 3000 1000 0
							 4520 1300 1000 1>;
				bcc_temp_160_to_400 =	<4484 4000 3000 0
							 4514 3000 1000 0
							 4520 1300 1000 1>;
				bcc_temp_400_to_440 =	<4484 4000 3000 0
							 4514 3000 1000 0
							 4520 1300 1000 1>;
			};

			bcc_soc_70_to_90 {
				bcc_temp_0_to_50 =	<4460 1000 1000 1>;
				bcc_temp_50_to_120 =	<4460 1000 1000 1>;
				bcc_temp_120_to_160 =	<4514 3000 1000 0
							 4520 1300 1000 1>;
				bcc_temp_160_to_400 =	<4514 3000 1000 0
							 4520 1300 1000 1>;
				bcc_temp_400_to_440 =	<4514 3000 1000 0
							 4520 1300 1000 1>;
			};
		};
	};
};

&soc {
	oplus_virtual_rx: oplus,virtual_rx {
		compatible = "oplus,virtual_rx";
		oplus,rx_ic = <&oplus_p9415>;
		oplus,rx_ic_index = <0>;
		oplus,rx_ic_func_group = <&p9415_rx_groups>;
		oplus,ic_type = <OPLUS_CHG_IC_VIRTUAL_RX>;
		oplus,ic_index = <0>;
	};

	oplus_virtual_cp: oplus,virtual_cp {
		compatible = "oplus,virtual_cp";
		oplus,cp_ic = <&oplus_hl7227>;
		oplus,cp_ic_connect = <OPLUS_CHG_IC_CONNECT_PARALLEL>;
		oplus,main_cp = <0>;
		oplus,input_curr_max_ma = <2500>;
		oplus,cp_ic_func_group = <&hl7227_cp_groups>;
		oplus,ic_type = <OPLUS_CHG_IC_VIRTUAL_CP>;
		oplus,ic_index = <0>;
	};
};

&pm8550ve_gpios {
	cp_en_active: cp_en_active {
		pins = "gpio8";
		function = "normal";
		bias-disable;
		power-source = <0>;
		output-high;
		qcom,drive-strength = <3>;
	};

	cp_en_sleep: cp_en_sleep {
		pins = "gpio8";
		function = "normal";
		bias-disable;
		power-source = <0>;
		output-low;
		qcom,drive-strength = <3>;
	};
};

&qupv3_se15_2uart {
	pinctrl-1 = <&qupv3_se15_2uart_sleep_backup>;
	status = "okay";
};

&tlmm {
	qupv3_se15_2uart_sleep_backup:qupv3_se15_2uart_sleep_backup {
		mux {
			pins = "gpio30", "gpio31";
			function = "gpio";
		};

		config {
			pins = "gpio30", "gpio31";
			drive-strength = <2>;
			bias-disable;
			input-enable;
		};
	};

	cp_int_default: cp_int_default {
		mux {
			pins = "gpio181";
			function = "gpio";
		};
		config {
			pins = "gpio181";
			drive-strength = <2>;
			bias-disable;
			input-enable;
		};
	};
};

&tlmm {
	rx_event_default: rx_event_default {
		mux {
			pins = "gpio182";
			function = "gpio";
		};
		config {
			pins = "gpio182";
			drive-strength = <2>;
			input-enable;
			bias-disable;
		};
	};

	rx_con_default: rx_con_default {
		mux {
			pins = "gpio12";
			function = "gpio";
		};
		config {
			pins = "gpio12";
			drive-strength = <2>;
			bias-disable;
			input-enable;
		};
	};
};

&pm8550vs_c_gpios {
	rx_en_sleep: rx_en_sleep {
		pins = "gpio6";
		function = "normal";
		input-disable;
		bias-disable;
		power-source = <1>;
		output-high;
		qcom,drive-strength = <3>;
	};

	rx_en_active: rx_en_active {
		pins = "gpio6";
		function = "normal";
		input-disable;
		bias-disable;
		power-source = <1>;
		output-low;
		qcom,drive-strength = <3>;
	};
};

&pm8550vs_g_gpios {
	rx_mode_active: rx_mode_active {
		pins = "gpio5";
		function = "normal";
		input-disable;
		bias-disable;
		power-source = <1>;
		output-low;
		qcom,drive-strength = <3>;
	};

	rx_mode_sleep: rx_mode_sleep {
		pins = "gpio5";
		function = "normal";
		input-disable;
		bias-disable;
		power-source = <1>;
		output-high;
		qcom,drive-strength = <3>;
	};
};

&qupv3_hub_i2c3_sda_active {
	config {
		qcom,i2c_pull;
	};
};
&qupv3_hub_i2c3_scl_active {
	config {
		qcom,i2c_pull;
	};
};

&qupv3_hub_i2c3 {
	status = "ok";
	qcom,clk-freq-out = <400000>;

	oplus_hl7227: oplus,hl7227@51 {
		status = "ok";
		compatible = "oplus,cp-hl7227";
		reg = <0x51>;
		oplus,ic_type = <OPLUS_CHG_IC_CP>;
		oplus,ic_index = <0>;

		oplus,cp_en-gpio = <&pm8550ve_gpios 8 0x00>;//check
		oplus,cp_int-gpio = <&tlmm 181 0x00>;//check
		pinctrl-names = "cp_en_active", "cp_en_sleep", "cp_int_default";
		pinctrl-0 = <&cp_en_active>;
		pinctrl-1 = <&cp_en_sleep>;
		pinctrl-2 = <&cp_int_default>;
	};

	oplus_p9415: oplus,p9415@3b {
		status = "ok";
		compatible = "oplus,rx-p9415";
		reg = <0x3b>;
		#address-cells = <1>;
		#size-cells = <0>;
		oplus,ic_type = <OPLUS_CHG_IC_RX>;
		oplus,ic_index = <0>;
		oplus,nor_ic = <&oplus_virtual_buck>;
		oplus,support_epp_11w;

		oplus,rx_event-gpio = <&tlmm 182 0x00>;//check
		oplus,rx_con-gpio = <&tlmm 12 0x00>;//check
		oplus,rx_en-gpio = <&pm8550vs_c_gpios 6 0x00>;//vt-sleep check
		oplus,mode_sw-test-gpio = <&pm8550vs_g_gpios 5 0x00>;//check
		pinctrl-names = "rx_event_default", "rx_con_default",
				"rx_en_sleep", "rx_en_active",
				"rx_mode_active", "rx_mode_sleep";
		pinctrl-0 = <&rx_event_default>;
		pinctrl-1 = <&rx_con_default>;
		pinctrl-2 = <&rx_en_sleep>;
		pinctrl-3 = <&rx_en_active>;
		pinctrl-4 = <&rx_mode_active>;
		pinctrl-5 = <&rx_mode_sleep>;
	};
};
//#endif OPLUS_FEATURE_CHG_BASIC /*for wls charging config*/


//#ifdef OPLUS_FEATURE_CHG_BASIC /* BSP.CHG.Basic, 2023/04/19, sjc Add for ufcs */
//for ufcs config

&soc {
	oplus_cpa: oplus,cpa {
		compatible = "oplus,cpa";
		/* format: <protocol_type power_w> */
		oplus,protocol_list = <CHG_PROTOCOL_UFCS  33
				       CHG_PROTOCOL_PD   18
				       CHG_PROTOCOL_VOOC 100
				       CHG_PROTOCOL_QC   18
				       CHG_PROTOCOL_PPS  33>;
		oplus,default_protocol_list = <CHG_PROTOCOL_UFCS
					       CHG_PROTOCOL_PD
					       CHG_PROTOCOL_VOOC>;
	};

	oplus_ufcs_virtual_cp: oplus,ufcs_virtual_cp {
		compatible = "oplus,virtual_cp";

		oplus,ic_type = <OPLUS_CHG_IC_VIRTUAL_CP>;
		oplus,ic_index = <1>;

		oplus,cp_ic = <&oplus_adsp_mos>;
		oplus,input_curr_max_ma = <13700>;

		oplus,cp_ic_connect = <OPLUS_CHG_IC_CONNECT_PARALLEL>;
		oplus,main_cp = <0>;
	};

	oplus_virtual_platufcs: oplus,virtual_platufcs {
		compatible = "oplus,virtual_platufcs";

		oplus,ufcs_ic = <&oplus_adsp_ufcs>;
		oplus,ufcs_ic_index = <0>;
		oplus,ufcs_ic_connect = <OPLUS_CHG_IC_CONNECT_PARALLEL>;

		oplus,ufcs_ic_func_group = <&adsp_ufcs_groups>;
		oplus,ic_type = <OPLUS_CHG_IC_VIRTUAL_UFCS>;
		oplus,ic_index = <0>;
	};

	oplus_ufcs_charge: oplus,ufcs_charge {
		compatible = "oplus,ufcs_charge";
		oplus,ufcs_ic = <&oplus_virtual_platufcs>;
		oplus,cp_ic = <&oplus_ufcs_virtual_cp>;
		oplus,dpdm_switch_ic = <&oplus_adsp_dpdm_switch>;

		oplus,adsp_ufcs_project;
		oplus,impedance_unit = <&oplus_ufcs_impedance_unit>;

		oplus,target_vbus_mv = <11000>;
		oplus,curr_max_ma = <3000>;

		oplus,ufcs_warm_allow_vol = <4000>;
		oplus,ufcs_warm_allow_soc = <50>;
		oplus,ufcs_strategy_normal_current = <3000>;
		oplus,ufcs_over_high_or_low_current = <3000>;
		oplus,ufcs_timeout_third = <10800>;
		oplus,ufcs_timeout_oplus = <10800>;
		oplus,ufcs_ibat_over_third = <4000>;
		oplus,ufcs_ibat_over_oplus = <4000>;
		oplus,ufcs_full_cool_sw_vbat = <4540>;
		oplus,ufcs_full_normal_sw_vbat = <4540>;
		oplus,ufcs_full_normal_hw_vbat = <4550>;
		oplus,ufcs_full_ffc_vbat = <4520>;
		oplus,ufcs_full_warm_vbat = <4130>;
		oplus,ufcs_full_cool_sw_vbat_third = <4540>;
		oplus,ufcs_full_normal_sw_vbat_third= <4540>;
		oplus,ufcs_full_normal_hw_vbat_third = <4550>;
		oplus,ufcs_current_change_timeout = <100>;
		oplus,ufcs_strategy_batt_high_temp = <410 420 430 400 410 420>;
		oplus,ufcs_strategy_high_current = <3000 2000 2000 3000 3000 3000>;
		oplus,ufcs_charge_strategy_soc = <0 20 35 50 75 85 95>;
		oplus,ufcs_charge_strategy_temp = <0 50 120 200 350 440 530>;
		oplus,ufcs_low_curr_full_strategy_temp = <0 200 350 440>;

		ufcs_charge_low_curr_full {
			strategy_temp_little_cool = 	<950 4470 0
							 850 4465 0
							 750 4450 0
							 650 4440 0
							 550 4430 1>;
			strategy_temp_normal_low =	<950 4470 0
							 850 4465 0
							 750 4450 0
							 650 4440 0
							 550 4430 1>;
			strategy_temp_normal_high = 	<950 4470 0
							 850 4465 0
							 750 4450 0
							 650 4440 0
							 550 4430 1>;
		};

		ufcs_charge_third_strategy {
			oplus,temp_type = <OPLUS_STRATEGY_USE_SHELL_TEMP>;
			oplus,soc_range = <0 20 35 50 75 85 95>;
			oplus,temp_range = <0 50 120 200 350 440 530>;

			strategy_soc_range_min {
				strategy_temp_little_cold =	<11000 4150 3000 0 0
								11000 4350 2500 0 0
								11000 4350 2000 0 0
								11000 4460 1800 0 0
								11000 4460 1500 0 0
								11000 4470 1000 1 0>;
				strategy_temp_cool =		<11000 4350 3000 0 0
								11000 4350 2500 0 0
								11000 4350 2000 0 0
								11000 4460 1800 0 0
								11000 4460 1500 0 0
								11000 4470 1000 1 0>;
				strategy_temp_little_cool =	<11000 4460 3000 0 0
								11000 4460 2500 0 0
								11000 4460 2000 0 0
								11000 4470 1450 0 0
								11000 4470 1000 1 0>;
				strategy_temp_normal_low =	<11000 4460 3000 0 0
								11000 4460 2500 0 0
								11000 4460 2000 0 0
								11000 4470 1450 0 0
								11000 4470 1000 1 0>;
				strategy_temp_normal_high =	<11000 4460 3000 0 0
								11000 4460 2500 0 0
								11000 4460 2000 0 0
								11000 4470 1600 0 0
								11000 4470 1000 1 0>;
				strategy_temp_warm =		<11000 4130 1440 1 0>;
			};
			strategy_soc_range_low {
				strategy_temp_little_cold =	<11000 4150 3000 0 0
								11000 4350 2500 0 0
								11000 4350 2000 0 0
								11000 4460 1800 0 0
								11000 4460 1500 0 0
								11000 4470 1000 1 0>;
				strategy_temp_cool =		<11000 4350 3000 0 0
								11000 4350 2500 0 0
								11000 4350 2000 0 0
								11000 4460 1800 0 0
								11000 4460 1500 0 0
								11000 4470 1000 1 0>;
				strategy_temp_little_cool =	<11000 4460 3000 0 0
								11000 4460 2500 0 0
								11000 4460 2000 0 0
								11000 4470 1450 0 0
								11000 4470 1000 1 0>;
				strategy_temp_normal_low =	<11000 4460 3000 0 0
								11000 4460 2500 0 0
								11000 4460 2000 0 0
								11000 4470 1450 0 0
								11000 4470 1000 1 0>;
				strategy_temp_normal_high =	<11000 4460 3000 0 0
								11000 4460 2500 0 0
								11000 4460 2000 0 0
								11000 4470 1600 0 0
								11000 4470 1000 1 0>;
				strategy_temp_warm =		<11000 4130 1440 1 0>;
			};
			strategy_soc_range_mid_low {
				strategy_temp_little_cold =	<11000 4150 3000 0 0
								11000 4350 2500 0 0
								11000 4350 2000 0 0
								11000 4460 1800 0 0
								11000 4460 1500 0 0
								11000 4470 1000 1 0>;
				strategy_temp_cool =		<11000 4350 3000 0 0
								11000 4350 2500 0 0
								11000 4350 2000 0 0
								11000 4460 1800 0 0
								11000 4460 1500 0 0
								11000 4470 1000 1 0>;
				strategy_temp_little_cool =	<11000 4460 3000 0 0
								11000 4460 2500 0 0
								11000 4460 2000 0 0
								11000 4470 1450 0 0
								11000 4470 1000 1 0>;
				strategy_temp_normal_low =	<11000 4460 3000 0 0
								11000 4460 2500 0 0
								11000 4460 2000 0 0
								11000 4470 1450 0 0
								11000 4470 1000 1 0>;
				strategy_temp_normal_high =	<11000 4460 3000 0 0
								11000 4460 2500 0 0
								11000 4460 2000 0 0
								11000 4470 1600 0 0
								11000 4470 1000 1 0>;
				strategy_temp_warm =		<11000 4130 1440 1 0>;
			};
			strategy_soc_range_mid {
				strategy_temp_little_cold =	<11000 4350 2500 0 0
								11000 4350 2000 0 0
								11000 4460 1800 0 0
								11000 4460 1500 0 0
								11000 4470 1000 1 0>;
				strategy_temp_cool =		<11000 4350 3000 0 0
								11000 4350 2500 0 0
								11000 4350 2000 0 0
								11000 4460 1800 0 0
								11000 4460 1500 0 0
								11000 4470 1000 1 0>;
				strategy_temp_little_cool =	<11000 4460 3000 0 0
								11000 4460 2500 0 0
								11000 4460 2000 0 0
								11000 4470 1450 0 0
								11000 4470 1000 1 0>;
				strategy_temp_normal_low =	<11000 4460 3000 0 0
								11000 4460 2500 0 0
								11000 4460 2000 0 0
								11000 4470 1450 0 0
								11000 4470 1000 1 0>;
				strategy_temp_normal_high =	<11000 4460 3000 0 0
								11000 4460 2500 0 0
								11000 4460 2000 0 0
								11000 4470 1600 0 0
								11000 4470 1000 1 0>;
				strategy_temp_warm =		<11000 4130 1100 1 0>;
			};
			strategy_soc_range_mid_high {
				strategy_temp_little_cold =	<11000 4460 1800 0 0
								11000 4460 1500 0 0
								11000 4470 1000 1 0>;
				strategy_temp_cool =		<11000 4460 1800 0 0
								11000 4460 1500 0 0
								11000 4470 1000 1 0>;
				strategy_temp_little_cool =	<11000 4460 3000 0 0
								11000 4460 2500 0 0
								11000 4460 2000 0 0
								11000 4470 1450 0 0
								11000 4470 1000 1 0>;
				strategy_temp_normal_low =	<11000 4460 3000 0 0
								11000 4460 2500 0 0
								11000 4460 2000 0 0
								11000 4470 1450 0 0
								11000 4470 1000 1 0>;
				strategy_temp_normal_high =	<11000 4460 3000 0 0
								11000 4460 2500 0 0
								11000 4460 2000 0 0
								11000 4470 1600 0 0
								11000 4470 1000 1 0>;
				strategy_temp_warm =		<11000 4130 1100 1 0>;
			};
			strategy_soc_range_high {
				strategy_temp_little_cold =	<11000 4470 1000 1 0>;
				strategy_temp_cool =		<11000 4470 1000 1 0>;
				strategy_temp_little_cool =	<11000 4460 2000 0 0
								11000 4470 1450 0 0
								11000 4470 1000 1 0>;
				strategy_temp_normal_low =	<11000 4460 2500 0 0
								11000 4460 2000 0 0
								11000 4470 1450 0 0
								11000 4470 1000 1 0>;
				strategy_temp_normal_high =	<11000 4460 2500 0 0
								11000 4460 2000 0 0
								11000 4470 1600 0 0
								11000 4470 1000 1 0>;
				strategy_temp_warm =		<11000 4130 1100 1 0>;
			};
		};

		ufcs_charge_oplus_strategy {
			oplus,temp_type = <OPLUS_STRATEGY_USE_SHELL_TEMP>;
			oplus,soc_range = <0 20 35 50 75 85 95>;
			oplus,temp_range = <0 50 120 200 350 440 530>;

			strategy_soc_range_min {
				strategy_temp_little_cold =	<11000 4180 2000 0 0
								11000 4420 1400 0 0
								11000 4430 1000 1 0>;
				strategy_temp_cool =		<11000 4180 2500 0 0
								11000 4420 2000 0 0
								11000 4420 1500 0 0
								11000 4430 1000 1 0>;
				strategy_temp_little_cool =	<11000 4350 3000 0 0
								11000 4350 2500 0 0
								11000 4480 2000 0 0
								11000 4480 1500 0 0
								11000 4490 1000 1 0>;
				strategy_temp_normal_low =	<11000 4450 3000 0 0
								11000 4450 2500 0 0
								11000 4480 2000 0 0
								11000 4480 1500 0 0
								11000 4490 1000 1 0>;
				strategy_temp_normal_high =	<11000 4450 3000 0 0
								11000 4450 2500 0 0
								11000 4480 2000 0 0
								11000 4480 1500 0 0
								11000 4490 1000 1 0>;
				strategy_temp_warm =		<11000 4130 1000 1 0>;
			};
			strategy_soc_range_low {
				strategy_temp_little_cold =	<11000 4180 2000 0 0
								11000 4420 1400 0 0
								11000 4430 1000 1 0>;
				strategy_temp_cool =		<11000 4180 2500 0 0
								11000 4420 2000 0 0
								11000 4420 1500 0 0
								11000 4430 1000 1 0>;
				strategy_temp_little_cool =	<11000 4350 3000 0 0
								11000 4350 2500 0 0
								11000 4480 2000 0 0
								11000 4480 1500 0 0
								11000 4490 1000 1 0>;
				strategy_temp_normal_low =	<11000 4450 3000 0 0
								11000 4450 2500 0 0
								11000 4480 2000 0 0
								11000 4480 1500 0 0
								11000 4490 1000 1 0>;
				strategy_temp_normal_high =	<11000 4450 3000 0 0
								11000 4450 2500 0 0
								11000 4480 2000 0 0
								11000 4480 1500 0 0
								11000 4490 1000 1 0>;
				strategy_temp_warm =		<11000 4130 1000 1 0>;
			};
			strategy_soc_range_mid_low {
				strategy_temp_little_cold =	<11000 4180 2000 0 0
								11000 4420 1400 0 0
								11000 4430 1000 1 0>;
				strategy_temp_cool =		<11000 4180 2500 0 0
								11000 4420 2000 0 0
								11000 4420 1500 0 0
								11000 4430 1000 1 0>;
				strategy_temp_little_cool =	<11000 4350 3000 0 0
								11000 4350 2500 0 0
								11000 4480 2000 0 0
								11000 4480 1500 0 0
								11000 4490 1000 1 0>;
				strategy_temp_normal_low =	<11000 4450 3000 0 0
								11000 4450 2500 0 0
								11000 4480 2000 0 0
								11000 4480 1500 0 0
								11000 4490 1000 1 0>;
				strategy_temp_normal_high =	<11000 4450 3000 0 0
								11000 4450 2500 0 0
								11000 4480 2000 0 0
								11000 4480 1500 0 0
								11000 4490 1000 1 0>;
				strategy_temp_warm =		<11000 4130 1000 1 0>;
			};
			strategy_soc_range_mid {
				strategy_temp_little_cold =	<11000 4430 1000 1 0>;
				strategy_temp_cool =		<11000 4420 1500 0 0
								11000 4430 1000 1 0>;
				strategy_temp_little_cool =	<11000 4480 2000 0 0
								11000 4480 1500 0 0
								11000 4490 1000 1 0>;
				strategy_temp_normal_low =	<11000 4450 2500 0 0
								11000 4480 2000 0 0
								11000 4480 1500 0 0
								11000 4490 1000 1 0>;
				strategy_temp_normal_high =	<11000 4450 2500 0 0
								11000 4480 2000 0 0
								11000 4480 1500 0 0
								11000 4490 1000 1 0>;
				strategy_temp_warm =		<11000 4130 1000 1 0>;
			};
			strategy_soc_range_mid_high {
				strategy_temp_little_cold =	<11000 4430 1000 1 0>;
				strategy_temp_cool =		<11000 4430 1000 1 0>;
				strategy_temp_little_cool =	<11000 4490 1000 1 0>;
				strategy_temp_normal_low =	<11000 4480 1500 0 0
								11000 4490 1000 1 0>;
				strategy_temp_normal_high =	<11000 4480 1500 0 0
								11000 4490 1000 1 0>;
				strategy_temp_warm =		<11000 4130 900 1 0>;
			};
			strategy_soc_range_high {
				strategy_temp_little_cold =	<11000 4430 1000 1 0>;
				strategy_temp_cool =		<11000 4430 1000 1 0>;
				strategy_temp_little_cool =	<11000 4490 1000 1 0>;
				strategy_temp_normal_low =	<11000 4490 1000 1 0>;
				strategy_temp_normal_high =	<11000 4490 1000 1 0>;
				strategy_temp_warm =		<11000 4130 900 1 0>;
			};
		};

		oplus,impedance_node {
			ufcs_input_impedance: ufcs_input_impedance {
				node_name = "ufcs_input";
				default_impedance_mohm = <95>;
				default_curr_ma = <3000>;
				current_drop_table = <
					40  3000
					90  3000
					140 2000
					200 2000
					260 0
				>;
			};
		};
	};
};

&soc {
	oplus_ufcs_impedance_check: oplus,ufcs_impedance_check {
		compatible = "oplus,impedance_check";

		oplus,impedance_unit {
			oplus_ufcs_impedance_unit: oplus,ufcs_impedance_unit {
				uint_name = "ufcs";
				default_curr_ma = <3000>;
				impedance_node = <&ufcs_input_impedance>;
			};
		};
	};
};

//#endif OPLUS_FEATURE_CHG_BASIC /*for ufcs config*/

//#endif OPLUS_FEATURE_CHG_BASIC
